# CH32X035 register map
Vendor: WCH Ltd.; File version: 1.0
Registers are 8-bit, read-write, reset 0x0 unless marked. A register's access mark holds for its fields unless they carry their own. Offsets are from the block's base; lines under a group give offsets from that group; [hi:lo] are bit positions; {n}, {i} and the like mark numbered series; 'fields as' and 'values as' point back to an identical list; <NAME> marks a mode.

## Memory map
0x40023400 USBFS size 0x400 — USB device registers.

## USBFS — USB device registers.
Base 0x40023400
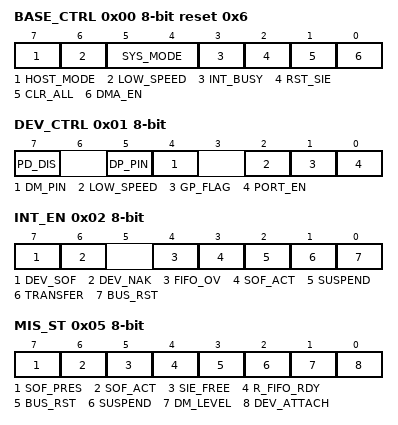
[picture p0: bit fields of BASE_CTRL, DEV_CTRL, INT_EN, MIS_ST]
0x00 BASE_CTRL reset 0x6 — USB control register.
  [7] HOST_MODE — USB operating mode selection bits.
  [6] LOW_SPEED — USB low speed enable bit.
  [5:4] SYS_MODE
  [3] INT_BUSY — USB transfer completion interrupt flag not cleared to zero auto pause enable bit.
  [2] RST_SIE — USB protocol processor software reset control.
  [1] CLR_ALL — USB FIFO and interrupt flag clear.
  [0] DMA_EN — Enables DMA for USB, this bit must be set to 1 in normal transfer mode.
0x01 DEV_CTRL access per field — USB device physical port control.
  [7] PD_DIS rw — USB device port UDP/UDM pulldown resistor disable.
  [5] DP_PIN ro — Current UDP pin state.
  [4] DM_PIN ro — Current UDM pin state.
  [2] LOW_SPEED rw — USB device port low speed enable.
  [1] GP_FLAG rw — General flag bit, user-defined.
  [0] PORT_EN rw — USB device physical port enable.
0x02 INT_EN — USB interrupt enable register.
  [7] DEV_SOF — USB device mode, receive SOF interrupt.
  [6] DEV_NAK — USB device mode, receive NAK interrupt.
  [4] FIFO_OV — FIFO overflow interrupt.
  [3] SOF_ACT — USB host mode, SOF receive completion interrupt.
  [2] SUSPEND — USB bus suspend or wakeup event interrupt.
  [1] TRANSFER — USB transfer (excluding SETUP transaction) completion interrupt.
  [0] BUS_RST — USB bus reset event interrupt.
0x03 DEV_ADDR — USB device address register.
  [6:0] USB_ADDR — USB device address.
0x05 MIS_ST ro — USB miscellaneous status register.
  [7] SOF_PRES — SOF packet presage status in USB host mode.
  [6] SOF_ACT — SOF packet transfer status in USB host mode.
  [5] SIE_FREE — USB protocol handler free.
  [4] R_FIFO_RDY — USB receive FIFO data ready.
  [3] BUS_RST — USB bus reset.
  [2] SUSPEND — USB suspend.
  [1] DM_LEVEL
  [0] DEV_ATTACH — USB device attach status for the port in USB host mode.
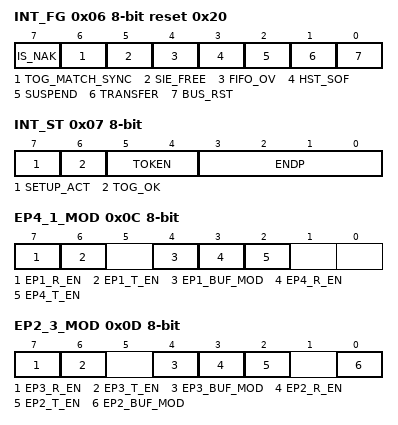
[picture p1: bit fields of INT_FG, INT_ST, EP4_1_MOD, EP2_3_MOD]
0x06 INT_FG access per field reset 0x20 — USB interrupt flag register.
  [7] IS_NAK ro — NAK response interrupt flag bit in USB device mode.
  [6] TOG_MATCH_SYNC ro — Toggle bit of received packet matched expected.
  [5] SIE_FREE ro — USB protocol handler free.
  [4] FIFO_OV rw — USB FIFO overflow interrupt flag, write 1 to clear.
  [3] HST_SOF rw — SOF timer interrupt flag in USB host mode, write 1 to clear.
  [2] SUSPEND rw — USB bus suspend or wake-up event interrupt flag, write 1 to clear.
  [1] TRANSFER rw — USB transfer completion interrupt flag, write 1 to clear.
  [0] BUS_RST rw — In USB device mode, USB bus reset event interrupt flag bit, write 1 to clear.
0x07 INT_ST ro — USB interrupt status register.
  [7] SETUP_ACT — SETUP transaction completed.
  [6] TOG_OK — Toggle bit of received packet matched expected.
  [5:4] TOKEN — In device mode, the token PID identifier of XXb the current USB transfer transaction.
    0=OUT; 1=SOF; 2=IN; 3=SETUP
  [3:0] ENDP — In device mode, the endpoint number of the current USB transfer transaction.
0x08 RX_LEN 16-bit ro — USB receive length register.
  [6:0] RX_LEN — The current number of data bytes received by the USB endpoint.
0x0C EP4_1_MOD — Endpoint 1 and 4 mode control.
  [7] EP1_R_EN — Endpoint 1 receive enable.
  [6] EP1_T_EN — Endpoint 1 transmit enable.
  [4] EP1_BUF_MOD — Endpoint 1 buffer mode control.
  [3] EP4_R_EN — Endpoint 4 receive enable.
  [2] EP4_T_EN — Endpoint 4 transmit enable.
0x0D EP2_3_MOD — Endpoint 2 and 3 mode control.
  [7] EP3_R_EN — Endpoint 3 receive enable.
  [6] EP3_T_EN — Endpoint 3 transmit enable.
  [4] EP3_BUF_MOD — Endpoint 3 buffer mode control.
  [3] EP2_R_EN — Endpoint 2 receive enable.
  [2] EP2_T_EN — Endpoint 2 transmit enable.
  [0] EP2_BUF_MOD — Endpoint 2 buffer mode control.
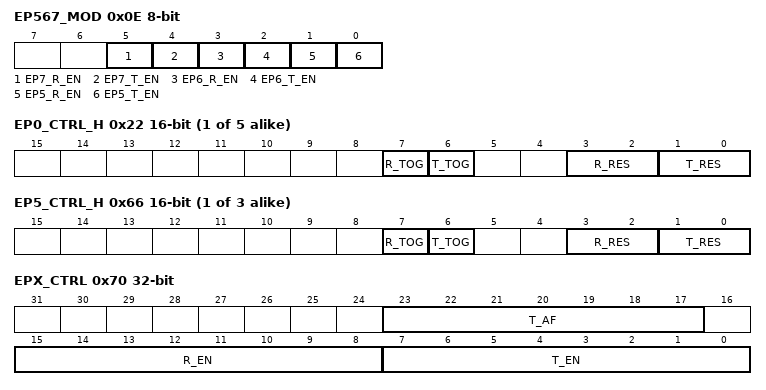
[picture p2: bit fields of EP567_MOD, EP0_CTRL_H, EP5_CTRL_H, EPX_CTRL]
0x0E EP567_MOD — Endpoint 5, 6 and 7 mode control.
  [5] EP7_R_EN — Endpoint 7 receive enable.
  [4] EP7_T_EN — Endpoint 7 transmit enable.
  [3] EP6_R_EN — Endpoint 6 receive enable.
  [2] EP6_T_EN — Endpoint 6 transmit enable.
  [1] EP5_R_EN — Endpoint 5 receive enable.
  [0] EP5_T_EN — Endpoint 5 transmit enable.
{0x10+4i} EP{i}_DMA (i=0..3) 32-bit — Start address of the endpoint buffer.
  [14:0] BUF_ADDR — Start address of the endpoint buffer, must be 4 byte aligned.
{0x20+4i} EP{i}_TX_LEN (i=0..4) 16-bit — Endpoint transmit length.
  [6:0] T_LEN — The number of bytes to be transmitted by the endpoint.
{0x22+4i} EP{i}_CTRL_H (i=0..4) 16-bit — Endpoint control register.
  [7] R_TOG — Endpoint receiver toggle bit.
  [6] T_TOG — Endpoint transmitter toggle bit.
  [3:2] R_RES — Endpoint receiver response control.
    0=ACK; 1=NYET; 2=NAK; 3=STALL
  [1:0] T_RES — Endpoint transmitter response control.
    0=ACK; 1=NYET; 2=NAK; 3=STALL
{0x40+4i} EP{i}_DMA (i=5..7) 32-bit — Start address of the endpoint buffer.
  fields as EP0_DMA
{0x50+4i} EP{i}_TX_LEN (i=5..7) 16-bit — Endpoint transmit length.
  [6:0] T_LEN — The number of bytes to be transmitted by the endpoint.
{0x52+4i} EP{i}_CTRL_H (i=5..7) 16-bit — Endpoint control register.
  fields as EP0_CTRL_H
0x70 EPX_CTRL 32-bit — Endpoint X control register.
  [23:17] T_AF — Transmit endpoint alternate enable.
  [15:8] R_EN — Endpoint (8-15) receive enable.
  [7:0] T_EN — Endpoint (8-15) transmit enable.
